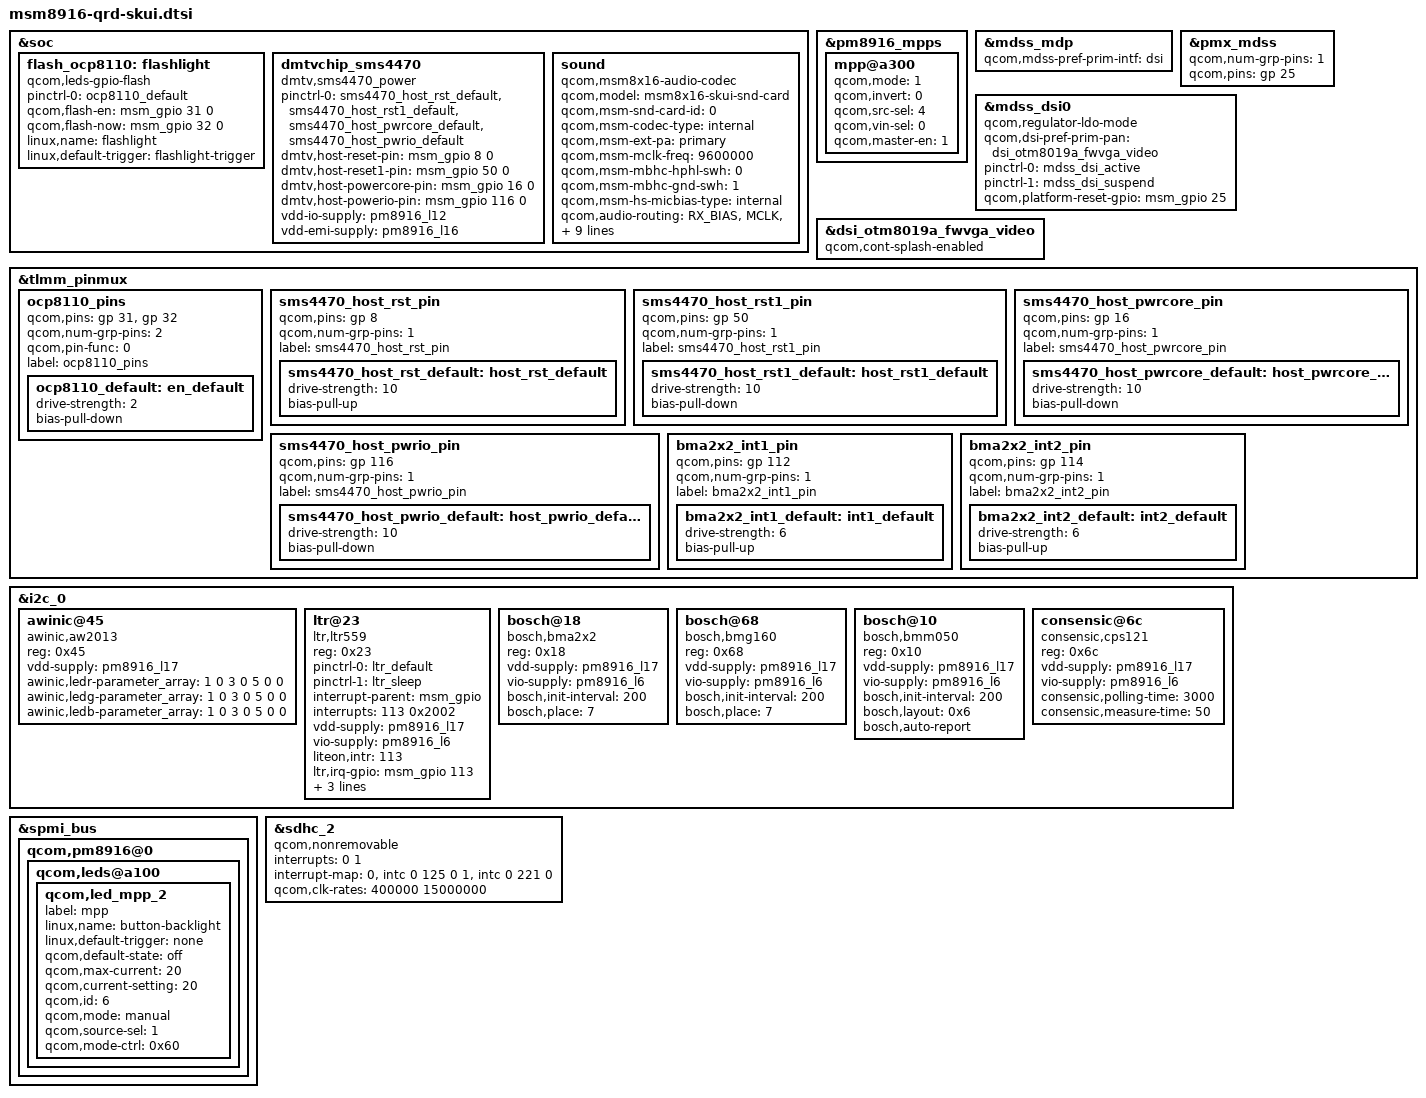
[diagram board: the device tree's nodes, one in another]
/* Copyright (c) 2014, The Linux Foundation. All rights reserved.
 *
 * This program is free software; you can redistribute it and/or modify
 * it under the terms of the GNU General Public License version 2 and
 * only version 2 as published by the Free Software Foundation.
 *
 * This program is distributed in the hope that it will be useful,
 * but WITHOUT ANY WARRANTY; without even the implied warranty of
 * MERCHANTABILITY or FITNESS FOR A PARTICULAR PURPOSE.  See the
 * GNU General Public License for more details.
 */

#include "msm8916-qrd.dtsi"
#include "dsi-panel-otm8019a-fwvga-video.dtsi"
#include "msm8916-camera-sensor-qrd-skui.dtsi"
#include "dsi-panel-trulyk70334-720p-video.dtsi"
#include "dsi-panel-trulyHX8394D-720p-video.dtsi"
#include "dsi-panel-boyiotm1284a-720p-video.dtsi"
#include "dsi-panel-trulyotm1288a-720p-cmd.dtsi"
&soc {
	flash_ocp8110:flashlight {
		compatible = "qcom,leds-gpio-flash";
		status = "okay";
		pinctrl-names = "ocp8110_default";
		pinctrl-0 = <&ocp8110_default>;
		qcom,flash-en = <&msm_gpio 31 0>;
		qcom,flash-now = <&msm_gpio 32 0>;
		linux,name = "flashlight";
		linux,default-trigger = "flashlight-trigger";
	};
	
	dmtvchip_sms4470{
		compatible = "dmtv,sms4470_power";
		status = "okay";
		pinctrl-names = "default";
		pinctrl-0 = <&sms4470_host_rst_default &sms4470_host_rst1_default &sms4470_host_pwrcore_default &sms4470_host_pwrio_default>;
		dmtv,host-reset-pin = <&msm_gpio 8 0>;
		dmtv,host-reset1-pin = <&msm_gpio 50 0>;
		dmtv,host-powercore-pin = <&msm_gpio 16 0>;
		dmtv,host-powerio-pin = <&msm_gpio 116 0>;
		vdd-io-supply = <&pm8916_l12>;
		vdd-emi-supply = <&pm8916_l16>;
	};

	/*gpio-leds {
		compatible = "gpio-leds";
		status = "okay";
		pinctrl-names = "default";
		pinctrl-0 = <&button_backlight_off>;

		keypad-backlight {
			gpios = <&msm_gpio 119 0>;
			label = "button-backlight";
			linux,default-trigger = "none";
		};
	};*/

	sound {
		compatible = "qcom,msm8x16-audio-codec";
		qcom,model = "msm8x16-skui-snd-card";
		qcom,msm-snd-card-id = <0>;
		qcom,msm-codec-type = "internal";
		qcom,msm-ext-pa = "primary";
		qcom,msm-mclk-freq = <9600000>;
		qcom,msm-mbhc-hphl-swh = <0>;
		qcom,msm-mbhc-gnd-swh = <1>;
		qcom,msm-hs-micbias-type = "internal";
		qcom,audio-routing =
			"RX_BIAS", "MCLK",
			"SPK_RX_BIAS", "MCLK",
			"INT_LDO_H", "MCLK",
			"MIC BIAS Internal1", "Handset Mic",
			"MIC BIAS Internal2", "Headset Mic",
			"MIC BIAS Internal1", "Secondary Mic",
			"AMIC1", "MIC BIAS Internal1",
			"AMIC2", "MIC BIAS Internal2",
			"AMIC3", "MIC BIAS Internal1";
		pinctrl-names = "cdc_lines_act",
				"cdc_lines_sus";
		pinctrl-0 = <&cdc_pdm_lines_act>;
		pinctrl-1 = <&cdc_pdm_lines_sus>;
	};
};

&pm8916_mpps {
	mpp@a300 { /* MPP 4 */
		/* Backlight PWM */
		qcom,mode = <1>;		/* Digital output */
		qcom,invert = <0>;		/* Disable Invert */
		qcom,src-sel = <4>;		/* DTEST1 */
		qcom,vin-sel = <0>;		/* VPH_PWR */
		qcom,master-en = <1>;		/* Enable MPP */
	};
};

&mdss_mdp {
	qcom,mdss-pref-prim-intf = "dsi";
};

&pmx_mdss {
	qcom,num-grp-pins = <1>;
	qcom,pins = <&gp 25>;
};

&mdss_dsi0 {
	qcom,regulator-ldo-mode;
	qcom,dsi-pref-prim-pan = <&dsi_otm8019a_fwvga_video>;
	pinctrl-names = "mdss_default", "mdss_sleep";
	pinctrl-0 = <&mdss_dsi_active>;
	pinctrl-1 = <&mdss_dsi_suspend>;

	qcom,platform-reset-gpio = <&msm_gpio 25 0>;
};

&dsi_otm8019a_fwvga_video {
       qcom,cont-splash-enabled;
};

&tlmm_pinmux {
	ocp8110_pins {
		qcom,pins = <&gp 31>, <&gp 32>;
		qcom,num-grp-pins = <2>;
		qcom,pin-func = <0>;
		label = "ocp8110_pins";
		ocp8110_default: en_default {
			  drive-strength = <2>;
			  bias-pull-down;
		};
	};

	sms4470_host_rst_pin {
		qcom,pins = <&gp 8>;
		qcom,num-grp-pins = <1>;
		label = "sms4470_host_rst_pin";
		sms4470_host_rst_default: host_rst_default {
			  drive-strength = <10>;
			  bias-pull-up;
		};
	};

	sms4470_host_rst1_pin {
		qcom,pins = <&gp 50>;
		qcom,num-grp-pins = <1>;
		label = "sms4470_host_rst1_pin";
		sms4470_host_rst1_default: host_rst1_default {
			  drive-strength = <10>;
			  bias-pull-down;
		};
	};

	sms4470_host_pwrcore_pin {
		qcom,pins = <&gp 16>;
		qcom,num-grp-pins = <1>;
		label = "sms4470_host_pwrcore_pin";
		sms4470_host_pwrcore_default: host_pwrcore_default {
			  drive-strength = <10>;
			  bias-pull-down;
		};
	};

	sms4470_host_pwrio_pin {
		qcom,pins = <&gp 116>;
		qcom,num-grp-pins = <1>;
		label = "sms4470_host_pwrio_pin";
		sms4470_host_pwrio_default: host_pwrio_default {
			  drive-strength = <10>;
			  bias-pull-down;
		};
	};

	bma2x2_int1_pin {
		qcom,pins = <&gp 112>;
		qcom,num-grp-pins = <1>;
		label = "bma2x2_int1_pin";
		bma2x2_int1_default: int1_default {
			  drive-strength = <6>;
			  bias-pull-up;
		};
	};

	bma2x2_int2_pin {
		qcom,pins = <&gp 114>;
		qcom,num-grp-pins = <1>;
		label = "bma2x2_int2_pin";
		bma2x2_int2_default: int2_default {
			  drive-strength = <6>;
			  bias-pull-up;
		};
	};
};

&i2c_0 { /* BLSP1 QUP2 */
		awinic@45 { /* Breath Light-Driven */
			/*
			led_Imax				current;         //0=omA, 1=5mA, 2=10mA, 3=15mA,
			unsigned int			rise_time;      //0=0.13s, 1=0.26s, 2=0.52s, 3=1.04s, 4=2.08s, 5=4.16s, 6=8.32s, 7=16.64s
			unsigned int			hold_time;     //0=0.13s, 1=0.26s, 2=0.52s, 3=1.04s, 4=2.08s, 5=4.16s,
			unsigned int			fall_time;       //0=0.13s, 1=0.26s, 2=0.52s, 3=1.04s, 4=2.08s, 5=4.16s, 6=8.32s, 7=16.64s
			unsigned int			off_time;       //0=0.13s, 1=0.26s, 2=0.52s, 3=1.04s, 4=2.08s, 5=4.16s, 6=8.32s, 7=16.64s
			unsigned int			delay_time;   //0=0.0s, 1=0.13s, 2=0.26s, 3=0.52s, 4=1.04s, 5=2.08s, 6=4.16s, 7=8.32s, 8=16.64s
			unsigned int			period_num; //0=unlimited, 1, 2, 3, 4, ......, 15
			*/
			compatible = "awinic,aw2013";
			reg = <0x45>;
			vdd-supply = <&pm8916_l17>;
			awinic,ledr-parameter_array = <1 0 3 0 5 0 0>;
			awinic,ledg-parameter_array = <1 0 3 0 5 0 0>;
			awinic,ledb-parameter_array = <1 0 3 0 5 0 0>;
		};

	        ltr@23 { /* Ambient light and proximity sensor */
	                compatible = "ltr,ltr559";
	                reg = <0x23>;
			pinctrl-names = "default","sleep";
			pinctrl-0 = <&ltr_default>;
			pinctrl-1 = <&ltr_sleep>;
	                interrupt-parent = <&msm_gpio>;
	                interrupts = <113 0x2002>;
	                vdd-supply = <&pm8916_l17>;
	                vio-supply = <&pm8916_l6>;
	                liteon,intr = <113>;
	                ltr,irq-gpio = <&msm_gpio 113 0x2002>;
	                ltr,ps-threshold = <120>;
	                ltr,ps-hysteresis-threshold = <80>;
	                ltr,als-polling-time = <200>;
	        };

		bosch@18 { /* Accelerometer sensor */
			compatible = "bosch,bma2x2";
			reg = <0x18>;
			vdd-supply = <&pm8916_l17>;
			vio-supply = <&pm8916_l6>;
			bosch,init-interval = <200>;
			bosch,place = <7>;
		};

		bosch@68 { /* Gyroscope sensor */
			compatible = "bosch,bmg160";
			reg = <0x68>;
			vdd-supply = <&pm8916_l17>;
			vio-supply = <&pm8916_l6>;
			bosch,init-interval = <200>;
			bosch,place = <7>;
		};

		bosch@10 {/* Magnetic sensor */
			compatible = "bosch,bmm050";
			reg = <0x10>;
			vdd-supply = <&pm8916_l17>;
			vio-supply = <&pm8916_l6>;
			bosch,init-interval = <200>;
			bosch,layout = <0x6>;
			bosch,auto-report;
		};

		consensic@6c {/* Barometer sensor */
			compatible = "consensic,cps121";
			reg = <0x6c>;
			vdd-supply = <&pm8916_l17>;
			vio-supply = <&pm8916_l6>;
			consensic,polling-time = <3000>;
			consensic,measure-time = <50>;
		};
	/*
	avago@39 { // Ambient light and proximity sensor
		compatible = "avago,apds9930";
		reg = <0x39>;
		pinctrl-names = "default","sleep";
		pinctrl-0 = <&apds99xx_default>;
		pinctrl-1 = <&apds99xx_sleep>;
		interrupt-parent = <&msm_gpio>;
		interrupts = <113 0x2002>;
		vdd-supply = <&pm8916_l17>;
		vio-supply = <&pm8916_l6>;
		avago,irq-gpio = <&msm_gpio 113 0x2002>;
		avago,ps-threshold = <600>;
		avago,ps-hysteresis-threshold = <500>;
		avago,ps-pulse = <8>;
		avago,ps-pgain = <0>;
		avago,als-B = <186>;
		avago,als-C = <75>;
		avago,als-D = <129>;
		avago,ga-value = <768>;
	};

	bosch@18 { // Accelerometer sensor
		compatible = "bosch,bma2x2";
		reg = <0x18>;
		pinctrl-names = "default";
		pinctrl-0 = <&bma2x2_int1_default &bma2x2_int2_default>;
		interrupt-parent = <&msm_gpio>;
		interrupts = <112 0x2002>;
		vdd-supply = <&pm8916_l17>;
		vio-supply = <&pm8916_l6>;
		bosch,init-interval = <200>;
		bosch,place = <2>;
		bosch,gpio-int1 = <&msm_gpio 112 0x2002>;
		bosch,gpio-int2 = <&msm_gpio 114 0x2002>;
	};

	mpu6050@68 {
		compatible = "invn,mpu6050";
		reg = <0x68>;
		pinctrl-names = "mpu_default","mpu_sleep";
		pinctrl-0 = <&mpu6050_default>;
		pinctrl-1 = <&mpu6050_sleep>;
		interrupt-parent = <&msm_gpio>;
		interrupts = <115 0x2>;
		vdd-supply = <&pm8916_l17>;
		vlogic-supply = <&pm8916_l16>;
		vi2c-supply = <&pm8916_l6>;
		invn,gpio-int = <&msm_gpio 115 0x2>;
		invn,place = "Portrait Up Back Side";
	};

	memsic@30 { // Magnetic field sensor
		compatible = "memsic,mmc3416x";
		reg = <0x30>;
		vdd-supply = <&pm8916_l17>;
		vio-supply = <&pm8916_l6>;
		memsic,dir = "obverse-x-axis-forward";
		memsic,auto-report;
	};*/
};

&spmi_bus {
        qcom,pm8916@0 {
                qcom,leds@a100 {
                        status = "okay";
                        qcom,led_mpp_2 {
                                label = "mpp";
                                linux,name = "button-backlight";
                                linux,default-trigger = "none";
                                qcom,default-state = "off";
                                qcom,max-current = <20>;
                                qcom,current-setting = <20>;
                                qcom,id = <6>;
                                qcom,mode = "manual";
                                qcom,source-sel = <1>;
                                qcom,mode-ctrl = <0x60>;
                        };
                };
        };
};

&sdhc_2 {
	qcom,nonremovable;

	interrupts = <0 1>;
	interrupt-map = <0 &intc 0 125 0
		1 &intc 0 221 0>;
	interrupt-names = "hc_irq", "pwr_irq";
	
	qcom,clk-rates = <400000 15000000>;
	/delete-property/ cd-gpios;
};

